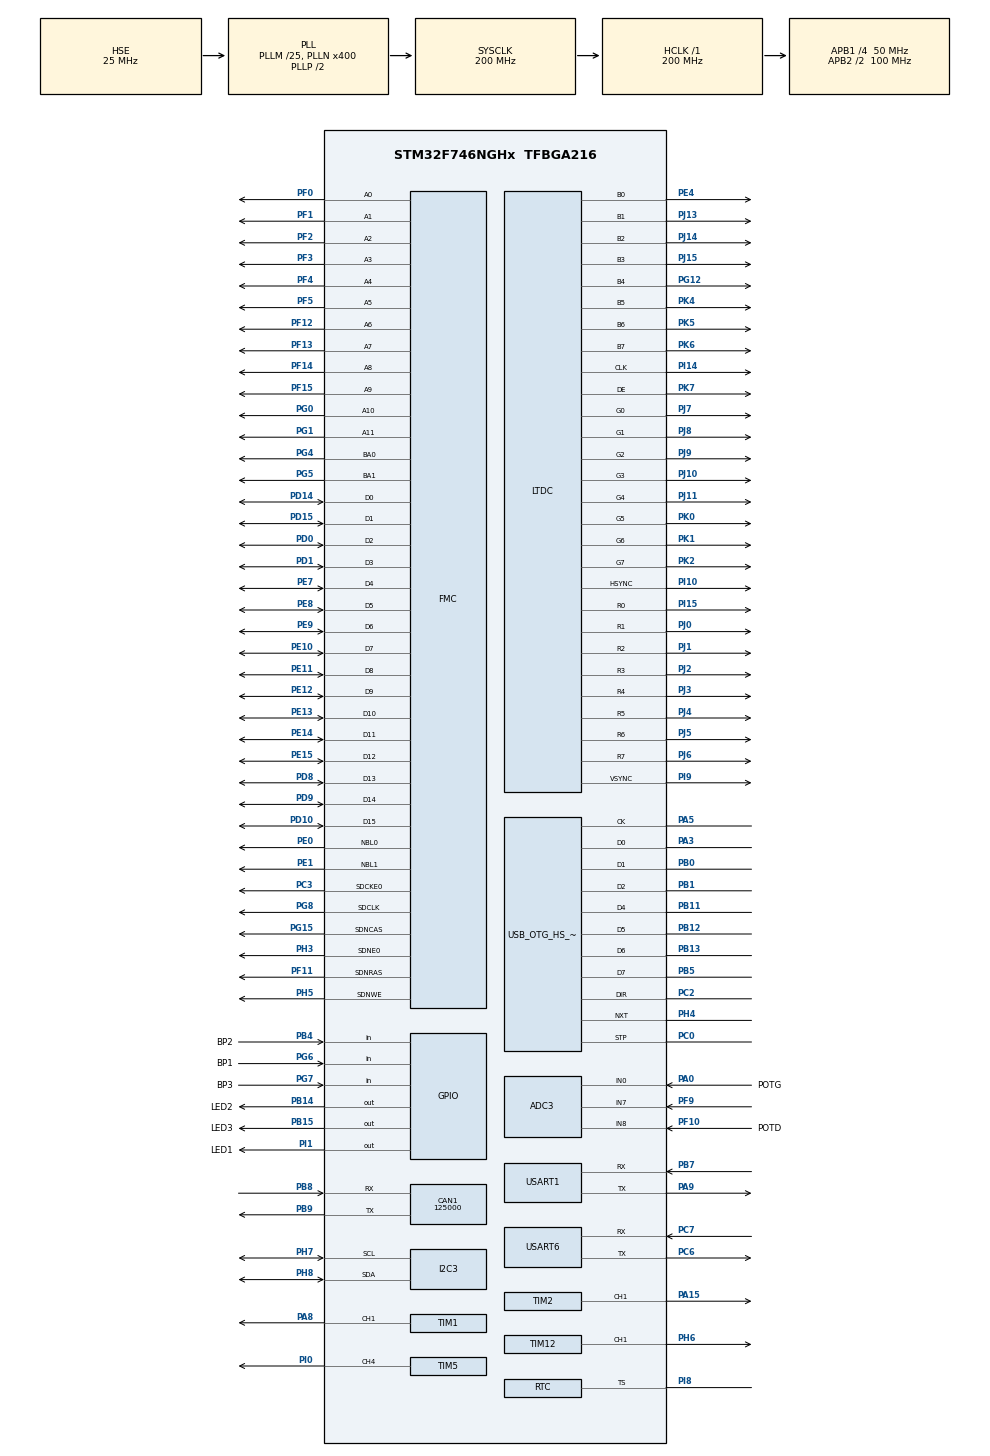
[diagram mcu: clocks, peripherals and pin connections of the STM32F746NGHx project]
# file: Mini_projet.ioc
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ADC1.Channel-0\#ChannelRegularConversion=ADC_CHANNEL_TEMPSENSOR
ADC1.NbrOfConversionFlag=1
ADC1.Rank-0\#ChannelRegularConversion=1
ADC1.SamplingTime-0\#ChannelRegularConversion=ADC_SAMPLETIME_3CYCLES
ADC1.master=1
ADC3.Channel-0\#ChannelRegularConversion=ADC_CHANNEL_0
ADC3.NbrOfConversionFlag=1
ADC3.Rank-0\#ChannelRegularConversion=1
ADC3.SamplingTime-0\#ChannelRegularConversion=ADC_SAMPLETIME_3CYCLES
CAN1.BS1=CAN_BS1_16TQ
CAN1.BS2=CAN_BS2_8TQ
CAN1.CalculateBaudRate=125000
CAN1.CalculateTimeBit=8000
CAN1.CalculateTimeQuantum=320.0
CAN1.SJW=CAN_SJW_2TQ
FMC.CASLatency1=FMC_SDRAM_CAS_LATENCY_3
FMC.ExitSelfRefreshDelay1=7
FMC.LoadToActiveDelay1=2
FMC.RCDDelay1=2
FMC.RPDelay1=2
FMC.RPDelay2=2
FMC.ReadBurst1=FMC_SDRAM_RBURST_ENABLE
FMC.ReadBurst2=FMC_SDRAM_RBURST_ENABLE
FMC.RowCycleDelay1=7
FMC.RowCycleDelay2=7
FMC.SDClockPeriod1=FMC_SDRAM_CLOCK_PERIOD_2
FMC.SDClockPeriod2=FMC_SDRAM_CLOCK_PERIOD_2
FMC.SelfRefreshTime1=4
FMC.WriteRecoveryTime1=3
FREERTOS.INCLUDE_vTaskDelayUntil=1
FREERTOS.Mutexes01=Mutex_layer,Dynamic,NULL
FREERTOS.Queues01=myQueue02,32,Message,0,Dynamic,NULL,NULL
FREERTOS.Tasks01=defaultTask,0,128,StartDefaultTask,Default,NULL,Dynamic,NULL,NULL;tache1,1,1024,affichage_1,Default,NULL,Dynamic,NULL,NULL;tache3,2,1024,update_state,Default,NULL,Dynamic,NULL,NULL;tache4,1,128,touch_confirm,Default,NULL,Dynamic,NULL,NULL
FREERTOS.configUSE_NEWLIB_REENTRANT=1
I2C3.Timing=0x00C0EAFF
LTDC.ActiveH=272
LTDC.ActiveW=480
LTDC.Alpha_L0=255
LTDC.BlendingFactor1_L0=LTDC_BLENDING_FACTOR1_PAxCA
LTDC.BlendingFactor2_L0=LTDC_BLENDING_FACTOR2_PAxCA
LTDC.FBStartAdress_L0=0xC0000000
LTDC.HBP=13
LTDC.HFP=32
LTDC.HSync=41
LTDC.ImageHeight_L0=272
LTDC.ImageWidth_L0=480
LTDC.Layers=0
LTDC.PixelFormat_L0=LTDC_PIXEL_FORMAT_RGB565
LTDC.VSync=10
LTDC.WindowX1_L0=480
LTDC.WindowY1_L0=272
Mcu.Family=STM32F7
Mcu.Name=STM32F746NGHx
Mcu.Package=TFBGA216
NVIC.CAN1_RX0_IRQn=true\:14\:0\:true\:false\:true\:true\:true\:true\:true
NVIC.DMA2D_IRQn=true\:5\:0\:false\:false\:true\:true\:true\:true\:true
NVIC.HASH_RNG_IRQn=true\:5\:0\:false\:false\:true\:true\:true\:true\:true
NVIC.LTDC_IRQn=true\:5\:0\:false\:false\:true\:true\:true\:true\:true
NVIC.PriorityGroup=NVIC_PRIORITYGROUP_4
NVIC.TIM6_DAC_IRQn=true\:15\:0\:false\:false\:true\:false\:false\:true\:true
NVIC.TimeBase=TIM6_DAC_IRQn
NVIC.TimeBaseIP=TIM6
PA0/WKUP.GPIO_Label=POTG
PA0/WKUP.Signal=ADCx_IN0
PA1.GPIO_Mode=GPIO_MODE_AF_PP
PA1.GPIO_PuPd=GPIO_NOPULL
PA1.GPIO_Speed=GPIO_SPEED_FREQ_VERY_HIGH
PA1.Signal=ETH_REF_CLK
PA10.GPIO_Mode=GPIO_MODE_AF_PP
PA10.GPIO_PuPd=GPIO_NOPULL
PA10.GPIO_Speed=GPIO_SPEED_FREQ_VERY_HIGH
PA10.Signal=USB_OTG_FS_ID
PA11.GPIO_Mode=GPIO_MODE_AF_PP
PA11.GPIO_PuPd=GPIO_NOPULL
PA11.GPIO_Speed=GPIO_SPEED_FREQ_VERY_HIGH
PA11.Signal=USB_OTG_FS_DM
PA12.GPIO_Mode=GPIO_MODE_AF_PP
PA12.GPIO_PuPd=GPIO_NOPULL
PA12.GPIO_Speed=GPIO_SPEED_FREQ_VERY_HIGH
PA12.Signal=USB_OTG_FS_DP
PA13.Signal=SYS_JTMS-SWDIO
PA14.Signal=SYS_JTCK-SWCLK
PA15.GPIO_ModeDefaultPP=GPIO_MODE_AF_PP
PA15.GPIO_PuPd=GPIO_NOPULL
PA15.GPIO_Speed=GPIO_SPEED_FREQ_LOW
PA15.Signal=S_TIM2_CH1_ETR
PA2.GPIO_Mode=GPIO_MODE_AF_PP
PA2.GPIO_PuPd=GPIO_NOPULL
PA2.GPIO_Speed=GPIO_SPEED_FREQ_VERY_HIGH
PA2.Signal=ETH_MDIO
PA3.GPIO_Mode=GPIO_MODE_AF_PP
PA3.GPIO_PuPd=GPIO_NOPULL
PA3.GPIO_Speed=GPIO_SPEED_FREQ_VERY_HIGH
PA3.Mode=Host_HS
PA3.Signal=USB_OTG_HS_ULPI_D0
PA4.GPIO_Mode=GPIO_MODE_AF_PP
PA4.GPIO_PuPd=GPIO_NOPULL
PA4.GPIO_Speed=GPIO_SPEED_FREQ_LOW
PA4.Signal=DCMI_HSYNC
PA5.GPIO_Mode=GPIO_MODE_AF_PP
PA5.GPIO_PuPd=GPIO_NOPULL
PA5.GPIO_Speed=GPIO_SPEED_FREQ_VERY_HIGH
PA5.Mode=Host_HS
PA5.Signal=USB_OTG_HS_ULPI_CK
PA6.Signal=DCMI_PIXCLK
PA7.GPIO_Mode=GPIO_MODE_AF_PP
PA7.GPIO_PuPd=GPIO_NOPULL
PA7.GPIO_Speed=GPIO_SPEED_FREQ_VERY_HIGH
PA7.Signal=ETH_CRS_DV
PA8.GPIO_ModeDefaultPP=GPIO_MODE_AF_PP
PA8.GPIO_PuPd=GPIO_NOPULL
PA8.GPIO_Speed=GPIO_SPEED_FREQ_LOW
PA8.Signal=S_TIM1_CH1
PA9.GPIO_Mode=GPIO_MODE_AF_PP
PA9.GPIO_ModeDefaultPP=GPIO_MODE_AF_PP
PA9.GPIO_PuPd=GPIO_NOPULL
PA9.GPIO_Speed=GPIO_SPEED_FREQ_VERY_HIGH
PA9.Mode=Asynchronous
PA9.Signal=USART1_TX
PB0.GPIO_Mode=GPIO_MODE_AF_PP
PB0.GPIO_PuPd=GPIO_NOPULL
PB0.GPIO_Speed=GPIO_SPEED_FREQ_VERY_HIGH
PB0.Mode=Host_HS
PB0.Signal=USB_OTG_HS_ULPI_D1
PB1.GPIO_Mode=GPIO_MODE_AF_PP
PB1.GPIO_PuPd=GPIO_NOPULL
PB1.GPIO_Speed=GPIO_SPEED_FREQ_VERY_HIGH
PB1.Mode=Host_HS
PB1.Signal=USB_OTG_HS_ULPI_D2
PB10.GPIO_Mode=GPIO_MODE_AF_PP
PB10.GPIO_PuPd=GPIO_NOPULL
PB10.GPIO_Speed=GPIO_SPEED_FREQ_VERY_HIGH
PB10.Signal=USB_OTG_HS_ULPI_D3
PB11.GPIO_Mode=GPIO_MODE_AF_PP
PB11.GPIO_PuPd=GPIO_NOPULL
PB11.GPIO_Speed=GPIO_SPEED_FREQ_VERY_HIGH
PB11.Mode=Host_HS
PB11.Signal=USB_OTG_HS_ULPI_D4
PB12.GPIO_Mode=GPIO_MODE_AF_PP
PB12.GPIO_PuPd=GPIO_NOPULL
PB12.GPIO_Speed=GPIO_SPEED_FREQ_VERY_HIGH
PB12.Mode=Host_HS
PB12.Signal=USB_OTG_HS_ULPI_D5
PB13.GPIO_Mode=GPIO_MODE_AF_PP
PB13.GPIO_PuPd=GPIO_NOPULL
PB13.GPIO_Speed=GPIO_SPEED_FREQ_VERY_HIGH
PB13.Mode=Host_HS
PB13.Signal=USB_OTG_HS_ULPI_D6
PB14.GPIO_Label=LED2
PB14.GPIO_ModeDefaultOutputPP=GPIO_MODE_OUTPUT_PP
PB14.GPIO_PuPd=GPIO_NOPULL
PB14.GPIO_Speed=GPIO_SPEED_FREQ_LOW
PB14.PinState=GPIO_PIN_RESET
PB14.Signal=GPIO_Output
PB15.GPIO_Label=LED3
PB15.GPIO_ModeDefaultOutputPP=GPIO_MODE_OUTPUT_PP
PB15.GPIO_PuPd=GPIO_NOPULL
PB15.GPIO_Speed=GPIO_SPEED_FREQ_LOW
PB15.PinState=GPIO_PIN_RESET
PB15.Signal=GPIO_Output
PB2.Signal=QUADSPI_CLK
PB3.Signal=SYS_JTDO-SWO
PB4.GPIO_Label=BP2
PB4.GPIO_Mode=GPIO_MODE_INPUT
PB4.GPIO_PuPd=GPIO_NOPULL
PB4.Signal=GPIO_Input
PB5.GPIO_Mode=GPIO_MODE_AF_PP
PB5.GPIO_PuPd=GPIO_NOPULL
PB5.GPIO_Speed=GPIO_SPEED_FREQ_VERY_HIGH
PB5.Mode=Host_HS
PB5.Signal=USB_OTG_HS_ULPI_D7
PB6.GPIO_Mode=GPIO_MODE_AF_PP
PB6.GPIO_PuPd=GPIO_NOPULL
PB6.GPIO_Speed=GPIO_SPEED_FREQ_VERY_HIGH
PB6.Signal=QUADSPI_BK1_NCS
PB7.GPIO_Mode=GPIO_MODE_AF_PP
PB7.GPIO_ModeDefaultPP=GPIO_MODE_AF_PP
PB7.GPIO_PuPd=GPIO_NOPULL
PB7.GPIO_Speed=GPIO_SPEED_FREQ_VERY_HIGH
PB7.Mode=Asynchronous
PB7.Signal=USART1_RX
PB8.Mode=CAN_Activate
PB8.Signal=CAN1_RX
PB9.Mode=CAN_Activate
PB9.Signal=CAN1_TX
PC0.GPIO_Mode=GPIO_MODE_AF_PP
PC0.GPIO_PuPd=GPIO_NOPULL
PC0.GPIO_Speed=GPIO_SPEED_FREQ_VERY_HIGH
PC0.Mode=Host_HS
PC0.Signal=USB_OTG_HS_ULPI_STP
PC1.GPIO_Mode=GPIO_MODE_AF_PP
PC1.GPIO_PuPd=GPIO_NOPULL
PC1.GPIO_Speed=GPIO_SPEED_FREQ_VERY_HIGH
PC1.Signal=ETH_MDC
PC10.GPIO_Mode=GPIO_MODE_AF_PP
PC10.GPIO_PuPd=GPIO_NOPULL
PC10.GPIO_Speed_High_Default=GPIO_SPEED_FREQ_VERY_HIGH
PC10.Signal=SDMMC1_D2
PC11.GPIO_Mode=GPIO_MODE_AF_PP
PC11.GPIO_PuPd=GPIO_NOPULL
PC11.GPIO_Speed_High_Default=GPIO_SPEED_FREQ_VERY_HIGH
PC11.Signal=SDMMC1_D3
PC12.GPIO_Mode=GPIO_MODE_AF_PP
PC12.GPIO_PuPd=GPIO_NOPULL
PC12.GPIO_Speed_High_Default=GPIO_SPEED_FREQ_VERY_HIGH
PC12.Signal=SDMMC1_CK
PC14/OSC32_IN.Mode=LSE-External-Oscillator
PC14/OSC32_IN.Signal=RCC_OSC32_IN
PC15/OSC32_OUT.Mode=LSE-External-Oscillator
PC15/OSC32_OUT.Signal=RCC_OSC32_OUT
PC2.GPIO_Mode=GPIO_MODE_AF_PP
PC2.GPIO_PuPd=GPIO_NOPULL
PC2.GPIO_Speed=GPIO_SPEED_FREQ_VERY_HIGH
PC2.Mode=Host_HS
PC2.Signal=USB_OTG_HS_ULPI_DIR
PC3.GPIO_Mode=GPIO_MODE_AF_PP
PC3.GPIO_PuPd=GPIO_NOPULL
PC3.GPIO_Speed_High_Default=GPIO_SPEED_FREQ_VERY_HIGH
PC3.Mode=SdramChipSelect1_1
PC3.Signal=FMC_SDCKE0
PC4.GPIO_Mode=GPIO_MODE_AF_PP
PC4.GPIO_PuPd=GPIO_NOPULL
PC4.GPIO_Speed=GPIO_SPEED_FREQ_VERY_HIGH
PC4.Signal=ETH_RXD0
PC5.GPIO_Mode=GPIO_MODE_AF_PP
PC5.GPIO_PuPd=GPIO_NOPULL
PC5.GPIO_Speed=GPIO_SPEED_FREQ_VERY_HIGH
PC5.Signal=ETH_RXD1
PC6.GPIO_ModeDefaultPP=GPIO_MODE_AF_PP
PC6.GPIO_PuPd=GPIO_NOPULL
PC6.GPIO_Speed=GPIO_SPEED_FREQ_VERY_HIGH
PC6.Mode=Asynchronous
PC6.Signal=USART6_TX
PC7.GPIO_ModeDefaultPP=GPIO_MODE_AF_PP
PC7.GPIO_PuPd=GPIO_NOPULL
PC7.GPIO_Speed=GPIO_SPEED_FREQ_VERY_HIGH
PC7.Mode=Asynchronous
PC7.Signal=USART6_RX
PC8.Signal=SDMMC1_D0
PC9.Signal=SDMMC1_D1
PD0.GPIO_Mode=GPIO_MODE_AF_PP
PD0.GPIO_PuPd=GPIO_NOPULL
PD0.GPIO_Speed_High_Default=GPIO_SPEED_FREQ_VERY_HIGH
PD0.Signal=FMC_D2_DA2
PD1.GPIO_Mode=GPIO_MODE_AF_PP
PD1.GPIO_PuPd=GPIO_NOPULL
PD1.GPIO_Speed_High_Default=GPIO_SPEED_FREQ_VERY_HIGH
PD1.Signal=FMC_D3_DA3
PD10.GPIO_Mode=GPIO_MODE_AF_PP
PD10.GPIO_PuPd=GPIO_NOPULL
PD10.GPIO_Speed_High_Default=GPIO_SPEED_FREQ_VERY_HIGH
PD10.Signal=FMC_D15_DA15
PD11.GPIO_Mode=GPIO_MODE_AF_PP
PD11.GPIO_PuPd=GPIO_NOPULL
PD11.GPIO_Speed=GPIO_SPEED_FREQ_VERY_HIGH
PD11.Signal=QUADSPI_BK1_IO0
PD12.GPIO_Mode=GPIO_MODE_AF_PP
PD12.GPIO_PuPd=GPIO_NOPULL
PD12.GPIO_Speed=GPIO_SPEED_FREQ_VERY_HIGH
PD12.Signal=QUADSPI_BK1_IO1
PD13.GPIO_Mode=GPIO_MODE_AF_PP
PD13.GPIO_PuPd=GPIO_NOPULL
PD13.GPIO_Speed=GPIO_SPEED_FREQ_VERY_HIGH
PD13.Signal=QUADSPI_BK1_IO3
PD14.GPIO_Mode=GPIO_MODE_AF_PP
PD14.GPIO_PuPd=GPIO_NOPULL
PD14.GPIO_Speed_High_Default=GPIO_SPEED_FREQ_VERY_HIGH
PD14.Signal=FMC_D0_DA0
PD15.GPIO_Mode=GPIO_MODE_AF_PP
PD15.GPIO_PuPd=GPIO_NOPULL
PD15.GPIO_Speed_High_Default=GPIO_SPEED_FREQ_VERY_HIGH
PD15.Signal=FMC_D1_DA1
PD2.GPIO_Mode=GPIO_MODE_AF_PP
PD2.GPIO_PuPd=GPIO_NOPULL
PD2.GPIO_Speed_High_Default=GPIO_SPEED_FREQ_VERY_HIGH
PD2.Signal=SDMMC1_CMD
PD3.GPIO_Mode=GPIO_MODE_AF_PP
PD3.GPIO_PuPd=GPIO_NOPULL
PD3.GPIO_Speed=GPIO_SPEED_FREQ_LOW
PD3.Signal=DCMI_D5
PD7.GPIO_Mode=GPIO_MODE_AF_PP
PD7.GPIO_PuPd=GPIO_NOPULL
PD7.GPIO_Speed=GPIO_SPEED_FREQ_LOW
PD7.Signal=SPDIFRX_IN0
PD8.GPIO_Mode=GPIO_MODE_AF_PP
PD8.GPIO_PuPd=GPIO_NOPULL
PD8.GPIO_Speed_High_Default=GPIO_SPEED_FREQ_VERY_HIGH
PD8.Signal=FMC_D13_DA13
PD9.GPIO_Mode=GPIO_MODE_AF_PP
PD9.GPIO_PuPd=GPIO_NOPULL
PD9.GPIO_Speed_High_Default=GPIO_SPEED_FREQ_VERY_HIGH
PD9.Signal=FMC_D14_DA14
PE0.GPIO_Mode=GPIO_MODE_AF_PP
PE0.GPIO_PuPd=GPIO_NOPULL
PE0.GPIO_Speed_High_Default=GPIO_SPEED_FREQ_VERY_HIGH
PE0.Signal=FMC_NBL0
PE1.GPIO_Mode=GPIO_MODE_AF_PP
PE1.GPIO_PuPd=GPIO_NOPULL
PE1.GPIO_Speed_High_Default=GPIO_SPEED_FREQ_VERY_HIGH
PE1.Signal=FMC_NBL1
PE10.GPIO_Mode=GPIO_MODE_AF_PP
PE10.GPIO_PuPd=GPIO_NOPULL
PE10.GPIO_Speed_High_Default=GPIO_SPEED_FREQ_VERY_HIGH
PE10.Signal=FMC_D7_DA7
PE11.GPIO_Mode=GPIO_MODE_AF_PP
PE11.GPIO_PuPd=GPIO_NOPULL
PE11.GPIO_Speed_High_Default=GPIO_SPEED_FREQ_VERY_HIGH
PE11.Signal=FMC_D8_DA8
PE12.GPIO_Mode=GPIO_MODE_AF_PP
PE12.GPIO_PuPd=GPIO_NOPULL
PE12.GPIO_Speed_High_Default=GPIO_SPEED_FREQ_VERY_HIGH
PE12.Signal=FMC_D9_DA9
PE13.GPIO_Mode=GPIO_MODE_AF_PP
PE13.GPIO_PuPd=GPIO_NOPULL
PE13.GPIO_Speed_High_Default=GPIO_SPEED_FREQ_VERY_HIGH
PE13.Signal=FMC_D10_DA10
PE14.GPIO_Mode=GPIO_MODE_AF_PP
PE14.GPIO_PuPd=GPIO_NOPULL
PE14.GPIO_Speed_High_Default=GPIO_SPEED_FREQ_VERY_HIGH
PE14.Signal=FMC_D11_DA11
PE15.GPIO_Mode=GPIO_MODE_AF_PP
PE15.GPIO_PuPd=GPIO_NOPULL
PE15.GPIO_Speed_High_Default=GPIO_SPEED_FREQ_VERY_HIGH
PE15.Signal=FMC_D12_DA12
PE2.GPIO_Mode=GPIO_MODE_AF_PP
PE2.GPIO_PuPd=GPIO_NOPULL
PE2.GPIO_Speed=GPIO_SPEED_FREQ_VERY_HIGH
PE2.Signal=QUADSPI_BK1_IO2
PE4.GPIO_Mode=GPIO_MODE_AF_PP
PE4.GPIO_PuPd=GPIO_NOPULL
PE4.GPIO_Speed=GPIO_SPEED_FREQ_LOW
PE4.Mode=RGB888
PE4.Signal=LTDC_B0
PE5.GPIO_Mode=GPIO_MODE_AF_PP
PE5.GPIO_PuPd=GPIO_NOPULL
PE5.GPIO_Speed=GPIO_SPEED_FREQ_LOW
PE5.Signal=DCMI_D6
PE6.GPIO_Mode=GPIO_MODE_AF_PP
PE6.GPIO_PuPd=GPIO_NOPULL
PE6.GPIO_Speed=GPIO_SPEED_FREQ_LOW
PE6.Signal=DCMI_D7
PE7.GPIO_Mode=GPIO_MODE_AF_PP
PE7.GPIO_PuPd=GPIO_NOPULL
PE7.GPIO_Speed_High_Default=GPIO_SPEED_FREQ_VERY_HIGH
PE7.Signal=FMC_D4_DA4
PE8.GPIO_Mode=GPIO_MODE_AF_PP
PE8.GPIO_PuPd=GPIO_NOPULL
PE8.GPIO_Speed_High_Default=GPIO_SPEED_FREQ_VERY_HIGH
PE8.Signal=FMC_D5_DA5
PE9.GPIO_Mode=GPIO_MODE_AF_PP
PE9.GPIO_PuPd=GPIO_NOPULL
PE9.GPIO_Speed_High_Default=GPIO_SPEED_FREQ_VERY_HIGH
PE9.Signal=FMC_D6_DA6
PF0.GPIO_Mode=GPIO_MODE_AF_PP
PF0.GPIO_PuPd=GPIO_NOPULL
PF0.GPIO_Speed_High_Default=GPIO_SPEED_FREQ_VERY_HIGH
PF0.Signal=FMC_A0
PF1.GPIO_Mode=GPIO_MODE_AF_PP
PF1.GPIO_PuPd=GPIO_NOPULL
PF1.GPIO_Speed_High_Default=GPIO_SPEED_FREQ_VERY_HIGH
PF1.Signal=FMC_A1
PF10.GPIO_Label=POTD
PF10.Mode=IN8
PF10.Signal=ADC3_IN8
PF11.GPIO_Mode=GPIO_MODE_AF_PP
PF11.GPIO_PuPd=GPIO_NOPULL
PF11.GPIO_Speed_High_Default=GPIO_SPEED_FREQ_VERY_HIGH
PF11.Signal=FMC_SDNRAS
PF12.GPIO_Mode=GPIO_MODE_AF_PP
PF12.GPIO_PuPd=GPIO_NOPULL
PF12.GPIO_Speed_High_Default=GPIO_SPEED_FREQ_VERY_HIGH
PF12.Signal=FMC_A6
PF13.GPIO_Mode=GPIO_MODE_AF_PP
PF13.GPIO_PuPd=GPIO_NOPULL
PF13.GPIO_Speed_High_Default=GPIO_SPEED_FREQ_VERY_HIGH
PF13.Signal=FMC_A7
PF14.GPIO_Mode=GPIO_MODE_AF_PP
PF14.GPIO_PuPd=GPIO_NOPULL
PF14.GPIO_Speed_High_Default=GPIO_SPEED_FREQ_VERY_HIGH
PF14.Signal=FMC_A8
PF15.GPIO_Mode=GPIO_MODE_AF_PP
PF15.GPIO_PuPd=GPIO_NOPULL
PF15.GPIO_Speed_High_Default=GPIO_SPEED_FREQ_VERY_HIGH
PF15.Signal=FMC_A9
PF2.GPIO_Mode=GPIO_MODE_AF_PP
PF2.GPIO_PuPd=GPIO_NOPULL
PF2.GPIO_Speed_High_Default=GPIO_SPEED_FREQ_VERY_HIGH
PF2.Signal=FMC_A2
PF3.GPIO_Mode=GPIO_MODE_AF_PP
PF3.GPIO_PuPd=GPIO_NOPULL
PF3.GPIO_Speed_High_Default=GPIO_SPEED_FREQ_VERY_HIGH
PF3.Signal=FMC_A3
PF4.GPIO_Mode=GPIO_MODE_AF_PP
PF4.GPIO_PuPd=GPIO_NOPULL
PF4.GPIO_Speed_High_Default=GPIO_SPEED_FREQ_VERY_HIGH
PF4.Signal=FMC_A4
PF5.GPIO_Mode=GPIO_MODE_AF_PP
PF5.GPIO_PuPd=GPIO_NOPULL
PF5.GPIO_Speed_High_Default=GPIO_SPEED_FREQ_VERY_HIGH
PF5.Signal=FMC_A5
PF6.GPIO_Mode=GPIO_MODE_ANALOG
PF6.GPIO_PuPd=GPIO_NOPULL
PF6.Signal=ADC3_IN4
PF7.GPIO_Mode=GPIO_MODE_ANALOG
PF7.GPIO_PuPd=GPIO_NOPULL
PF7.Signal=ADC3_IN5
PF8.GPIO_Mode=GPIO_MODE_ANALOG
PF8.GPIO_PuPd=GPIO_NOPULL
PF8.Signal=ADC3_IN6
PF9.GPIO_Mode=GPIO_MODE_ANALOG
PF9.GPIO_PuPd=GPIO_NOPULL
PF9.Mode=IN7
PF9.Signal=ADC3_IN7
PG0.GPIO_Mode=GPIO_MODE_AF_PP
PG0.GPIO_PuPd=GPIO_NOPULL
PG0.GPIO_Speed_High_Default=GPIO_SPEED_FREQ_VERY_HIGH
PG0.Signal=FMC_A10
PG1.GPIO_Mode=GPIO_MODE_AF_PP
PG1.GPIO_PuPd=GPIO_NOPULL
PG1.GPIO_Speed_High_Default=GPIO_SPEED_FREQ_VERY_HIGH
PG1.Signal=FMC_A11
PG10.GPIO_Mode=GPIO_MODE_AF_PP
PG10.GPIO_PuPd=GPIO_NOPULL
PG10.GPIO_Speed=GPIO_SPEED_FREQ_LOW
PG10.Signal=SAI2_SD_B
PG11.GPIO_Mode=GPIO_MODE_AF_PP
PG11.GPIO_PuPd=GPIO_NOPULL
PG11.GPIO_Speed=GPIO_SPEED_FREQ_VERY_HIGH
PG11.Signal=ETH_TX_EN
PG12.GPIO_Mode=GPIO_MODE_AF_PP
PG12.GPIO_PuPd=GPIO_NOPULL
PG12.GPIO_Speed=GPIO_SPEED_FREQ_LOW
PG12.Mode=RGB888
PG12.Signal=LTDC_B4
PG13.GPIO_Mode=GPIO_MODE_AF_PP
PG13.GPIO_PuPd=GPIO_NOPULL
PG13.GPIO_Speed=GPIO_SPEED_FREQ_VERY_HIGH
PG13.Signal=ETH_TXD0
PG14.GPIO_Mode=GPIO_MODE_AF_PP
PG14.GPIO_PuPd=GPIO_NOPULL
PG14.GPIO_Speed=GPIO_SPEED_FREQ_VERY_HIGH
PG14.Signal=ETH_TXD1
PG15.GPIO_Mode=GPIO_MODE_AF_PP
PG15.GPIO_PuPd=GPIO_NOPULL
PG15.GPIO_Speed_High_Default=GPIO_SPEED_FREQ_VERY_HIGH
PG15.Signal=FMC_SDNCAS
PG4.GPIO_Mode=GPIO_MODE_AF_PP
PG4.GPIO_PuPd=GPIO_NOPULL
PG4.GPIO_Speed_High_Default=GPIO_SPEED_FREQ_VERY_HIGH
PG4.Signal=FMC_A14_BA0
PG5.GPIO_Mode=GPIO_MODE_AF_PP
PG5.GPIO_PuPd=GPIO_NOPULL
PG5.GPIO_Speed_High_Default=GPIO_SPEED_FREQ_VERY_HIGH
PG5.Signal=FMC_A15_BA1
PG6.GPIO_Label=BP1
PG6.Signal=GPIO_Input
PG7.GPIO_Label=BP3
PG7.GPIO_Mode=GPIO_MODE_INPUT
PG7.GPIO_PuPd=GPIO_NOPULL
PG7.Signal=GPIO_Input
PG8.GPIO_Mode=GPIO_MODE_AF_PP
PG8.GPIO_PuPd=GPIO_NOPULL
PG8.GPIO_Speed_High_Default=GPIO_SPEED_FREQ_VERY_HIGH
PG8.Signal=FMC_SDCLK
PG9.GPIO_Mode=GPIO_MODE_AF_PP
PG9.GPIO_PuPd=GPIO_NOPULL
PG9.GPIO_Speed=GPIO_SPEED_FREQ_LOW
PG9.Signal=DCMI_VSYNC
PH0/OSC_IN.Mode=HSE-External-Oscillator
PH0/OSC_IN.Signal=RCC_OSC_IN
PH1/OSC_OUT.Mode=HSE-External-Oscillator
PH1/OSC_OUT.Signal=RCC_OSC_OUT
PH10.GPIO_Mode=GPIO_MODE_AF_PP
PH10.GPIO_PuPd=GPIO_NOPULL
PH10.GPIO_Speed=GPIO_SPEED_FREQ_LOW
PH10.Signal=DCMI_D1
PH11.GPIO_Mode=GPIO_MODE_AF_PP
PH11.GPIO_PuPd=GPIO_NOPULL
PH11.GPIO_Speed=GPIO_SPEED_FREQ_LOW
PH11.Signal=DCMI_D2
PH12.GPIO_Mode=GPIO_MODE_AF_PP
PH12.GPIO_PuPd=GPIO_NOPULL
PH12.GPIO_Speed=GPIO_SPEED_FREQ_LOW
PH12.Signal=DCMI_D3
PH14.GPIO_Mode=GPIO_MODE_AF_PP
PH14.GPIO_PuPd=GPIO_NOPULL
PH14.GPIO_Speed=GPIO_SPEED_FREQ_LOW
PH14.Signal=DCMI_D4
PH3.GPIO_Mode=GPIO_MODE_AF_PP
PH3.GPIO_PuPd=GPIO_NOPULL
PH3.GPIO_Speed_High_Default=GPIO_SPEED_FREQ_VERY_HIGH
PH3.Mode=SdramChipSelect1_1
PH3.Signal=FMC_SDNE0
PH4.GPIO_Mode=GPIO_MODE_AF_PP
PH4.GPIO_PuPd=GPIO_NOPULL
PH4.GPIO_Speed=GPIO_SPEED_FREQ_VERY_HIGH
PH4.Mode=Host_HS
PH4.Signal=USB_OTG_HS_ULPI_NXT
PH5.GPIO_Mode=GPIO_MODE_AF_PP
PH5.GPIO_PuPd=GPIO_NOPULL
PH5.GPIO_Speed_High_Default=GPIO_SPEED_FREQ_VERY_HIGH
PH5.Signal=FMC_SDNWE
PH6.GPIO_ModeDefaultPP=GPIO_MODE_AF_PP
PH6.GPIO_PuPd=GPIO_NOPULL
PH6.GPIO_Speed=GPIO_SPEED_FREQ_LOW
PH6.Signal=S_TIM12_CH1
PH7.GPIO_Mode=GPIO_MODE_AF_OD
PH7.GPIO_Pu=GPIO_PULLUP
PH7.GPIO_Speed=GPIO_SPEED_FREQ_VERY_HIGH
PH7.Mode=I2C
PH7.Signal=I2C3_SCL
PH8.GPIO_Mode=GPIO_MODE_AF_OD
PH8.GPIO_Pu=GPIO_PULLUP
PH8.GPIO_Speed=GPIO_SPEED_FREQ_VERY_HIGH
PH8.Mode=I2C
PH8.Signal=I2C3_SDA
PH9.GPIO_Mode=GPIO_MODE_AF_PP
PH9.GPIO_PuPd=GPIO_NOPULL
PH9.GPIO_Speed=GPIO_SPEED_FREQ_LOW
PH9.Signal=DCMI_D0
PI0.GPIO_ModeDefaultPP=GPIO_MODE_AF_PP
PI0.GPIO_PuPd=GPIO_NOPULL
PI0.GPIO_Speed=GPIO_SPEED_FREQ_LOW
PI0.Signal=S_TIM5_CH4
PI1.GPIO_Label=LED1
PI1.GPIO_ModeDefaultOutputPP=GPIO_MODE_OUTPUT_PP
PI1.GPIO_PuPd=GPIO_NOPULL
PI1.GPIO_Speed=GPIO_SPEED_FREQ_LOW
PI1.PinState=GPIO_PIN_RESET
PI1.Signal=GPIO_Output
PI10.GPIO_Mode=GPIO_MODE_AF_PP
PI10.GPIO_PuPd=GPIO_NOPULL
PI10.GPIO_Speed=GPIO_SPEED_FREQ_LOW
PI10.Mode=RGB888
PI10.Signal=LTDC_HSYNC
PI14.GPIO_Mode=GPIO_MODE_AF_PP
PI14.GPIO_PuPd=GPIO_NOPULL
PI14.GPIO_Speed=GPIO_SPEED_FREQ_LOW
PI14.Mode=RGB888
PI14.Signal=LTDC_CLK
PI15.GPIO_Mode=GPIO_MODE_AF_PP
PI15.GPIO_PuPd=GPIO_NOPULL
PI15.GPIO_Speed=GPIO_SPEED_FREQ_LOW
PI15.Mode=RGB888
PI15.Signal=LTDC_R0
PI4.GPIO_Mode=GPIO_MODE_AF_PP
PI4.GPIO_PuPd=GPIO_NOPULL
PI4.GPIO_Speed=GPIO_SPEED_FREQ_LOW
PI4.Signal=SAI2_MCLK_A
PI5.GPIO_Mode=GPIO_MODE_AF_PP
PI5.GPIO_PuPd=GPIO_NOPULL
PI5.GPIO_Speed=GPIO_SPEED_FREQ_LOW
PI5.Signal=SAI2_SCK_A
PI6.GPIO_Mode=GPIO_MODE_AF_PP
PI6.GPIO_PuPd=GPIO_NOPULL
PI6.GPIO_Speed=GPIO_SPEED_FREQ_LOW
PI6.Signal=SAI2_SD_A
PI7.GPIO_Mode=GPIO_MODE_AF_PP
PI7.GPIO_PuPd=GPIO_NOPULL
PI7.GPIO_Speed=GPIO_SPEED_FREQ_LOW
PI7.Signal=SAI2_FS_A
PI8.Mode=Timestamp enabled - Input Enabled to TS
PI8.Signal=RTC_TS
PI9.GPIO_Mode=GPIO_MODE_AF_PP
PI9.GPIO_PuPd=GPIO_NOPULL
PI9.GPIO_Speed=GPIO_SPEED_FREQ_LOW
PI9.Mode=RGB888
PI9.Signal=LTDC_VSYNC
PJ0.GPIO_Mode=GPIO_MODE_AF_PP
PJ0.GPIO_PuPd=GPIO_NOPULL
PJ0.GPIO_Speed=GPIO_SPEED_FREQ_LOW
PJ0.Mode=RGB888
PJ0.Signal=LTDC_R1
PJ1.GPIO_Mode=GPIO_MODE_AF_PP
PJ1.GPIO_PuPd=GPIO_NOPULL
PJ1.GPIO_Speed=GPIO_SPEED_FREQ_LOW
PJ1.Mode=RGB888
PJ1.Signal=LTDC_R2
PJ10.GPIO_Mode=GPIO_MODE_AF_PP
PJ10.GPIO_PuPd=GPIO_NOPULL
PJ10.GPIO_Speed=GPIO_SPEED_FREQ_LOW
PJ10.Mode=RGB888
PJ10.Signal=LTDC_G3
PJ11.GPIO_Mode=GPIO_MODE_AF_PP
PJ11.GPIO_PuPd=GPIO_NOPULL
PJ11.GPIO_Speed=GPIO_SPEED_FREQ_LOW
PJ11.Mode=RGB888
PJ11.Signal=LTDC_G4
PJ13.GPIO_Mode=GPIO_MODE_AF_PP
PJ13.GPIO_PuPd=GPIO_NOPULL
PJ13.GPIO_Speed=GPIO_SPEED_FREQ_LOW
PJ13.Mode=RGB888
PJ13.Signal=LTDC_B1
PJ14.GPIO_Mode=GPIO_MODE_AF_PP
PJ14.GPIO_PuPd=GPIO_NOPULL
PJ14.GPIO_Speed=GPIO_SPEED_FREQ_LOW
PJ14.Mode=RGB888
PJ14.Signal=LTDC_B2
PJ15.GPIO_Mode=GPIO_MODE_AF_PP
PJ15.GPIO_PuPd=GPIO_NOPULL
PJ15.GPIO_Speed=GPIO_SPEED_FREQ_LOW
PJ15.Mode=RGB888
PJ15.Signal=LTDC_B3
PJ2.GPIO_Mode=GPIO_MODE_AF_PP
PJ2.GPIO_PuPd=GPIO_NOPULL
PJ2.GPIO_Speed=GPIO_SPEED_FREQ_LOW
PJ2.Mode=RGB888
PJ2.Signal=LTDC_R3
PJ3.GPIO_Mode=GPIO_MODE_AF_PP
PJ3.GPIO_PuPd=GPIO_NOPULL
PJ3.GPIO_Speed=GPIO_SPEED_FREQ_LOW
PJ3.Mode=RGB888
PJ3.Signal=LTDC_R4
PJ4.GPIO_Mode=GPIO_MODE_AF_PP
PJ4.GPIO_PuPd=GPIO_NOPULL
PJ4.GPIO_Speed=GPIO_SPEED_FREQ_LOW
PJ4.Mode=RGB888
PJ4.Signal=LTDC_R5
PJ5.GPIO_Mode=GPIO_MODE_AF_PP
PJ5.GPIO_PuPd=GPIO_NOPULL
PJ5.GPIO_Speed=GPIO_SPEED_FREQ_LOW
PJ5.Mode=RGB888
PJ5.Signal=LTDC_R6
PJ6.GPIO_Mode=GPIO_MODE_AF_PP
PJ6.GPIO_PuPd=GPIO_NOPULL
PJ6.GPIO_Speed=GPIO_SPEED_FREQ_LOW
PJ6.Mode=RGB888
PJ6.Signal=LTDC_R7
PJ7.GPIO_Mode=GPIO_MODE_AF_PP
PJ7.GPIO_PuPd=GPIO_NOPULL
PJ7.GPIO_Speed=GPIO_SPEED_FREQ_LOW
PJ7.Mode=RGB888
PJ7.Signal=LTDC_G0
PJ8.GPIO_Mode=GPIO_MODE_AF_PP
PJ8.GPIO_PuPd=GPIO_NOPULL
PJ8.GPIO_Speed=GPIO_SPEED_FREQ_LOW
PJ8.Mode=RGB888
PJ8.Signal=LTDC_G1
PJ9.GPIO_Mode=GPIO_MODE_AF_PP
PJ9.GPIO_PuPd=GPIO_NOPULL
PJ9.GPIO_Speed=GPIO_SPEED_FREQ_LOW
PJ9.Mode=RGB888
PJ9.Signal=LTDC_G2
PK0.GPIO_Mode=GPIO_MODE_AF_PP
PK0.GPIO_PuPd=GPIO_NOPULL
PK0.GPIO_Speed=GPIO_SPEED_FREQ_LOW
PK0.Mode=RGB888
PK0.Signal=LTDC_G5
PK1.GPIO_Mode=GPIO_MODE_AF_PP
PK1.GPIO_PuPd=GPIO_NOPULL
PK1.GPIO_Speed=GPIO_SPEED_FREQ_LOW
PK1.Mode=RGB888
PK1.Signal=LTDC_G6
PK2.GPIO_Mode=GPIO_MODE_AF_PP
PK2.GPIO_PuPd=GPIO_NOPULL
PK2.GPIO_Speed=GPIO_SPEED_FREQ_LOW
PK2.Mode=RGB888
PK2.Signal=LTDC_G7
PK4.GPIO_Mode=GPIO_MODE_AF_PP
PK4.GPIO_PuPd=GPIO_NOPULL
PK4.GPIO_Speed=GPIO_SPEED_FREQ_LOW
PK4.Mode=RGB888
PK4.Signal=LTDC_B5
PK5.GPIO_Mode=GPIO_MODE_AF_PP
PK5.GPIO_PuPd=GPIO_NOPULL
PK5.GPIO_Speed=GPIO_SPEED_FREQ_LOW
PK5.Mode=RGB888
PK5.Signal=LTDC_B6
PK6.GPIO_Mode=GPIO_MODE_AF_PP
PK6.GPIO_PuPd=GPIO_NOPULL
PK6.GPIO_Speed=GPIO_SPEED_FREQ_LOW
PK6.Mode=RGB888
PK6.Signal=LTDC_B7
PK7.GPIO_Mode=GPIO_MODE_AF_PP
PK7.GPIO_PuPd=GPIO_NOPULL
PK7.GPIO_Speed=GPIO_SPEED_FREQ_LOW
PK7.Mode=RGB888
PK7.Signal=LTDC_DE
ProjectManager.HeapSize=0x200
ProjectManager.StackSize=0x400
ProjectManager.TargetToolchain=STM32CubeIDE
RCC.AHBFreq_Value=200000000
RCC.APB1CLKDivider=RCC_HCLK_DIV4
RCC.APB1Freq_Value=50000000
RCC.APB1TimFreq_Value=100000000
RCC.APB2CLKDivider=RCC_HCLK_DIV2
RCC.APB2Freq_Value=100000000
RCC.APB2TimFreq_Value=200000000
RCC.CortexFreq_Value=200000000
RCC.HCLKFreq_Value=200000000
RCC.HSE_VALUE=25000000
RCC.HSI_VALUE=16000000
RCC.PLL48CLockSelection=RCC_CLK48SOURCE_PLLSAIP
RCC.PLLI2SN=100
RCC.PLLM=25
RCC.PLLN=400
RCC.PLLQ=9
RCC.PLLSAIN=384
RCC.PLLSAIP=RCC_PLLSAIP_DIV8
RCC.PLLSAIR=5
RCC.PLLSAIRDiv=RCC_PLLSAIDIVR_8
RCC.PLLSourceVirtual=RCC_PLLSOURCE_HSE
RCC.SDMMCClockSelection=RCC_SDMMC1CLKSOURCE_CLK48
RCC.SYSCLKFreq_VALUE=200000000
RCC.SYSCLKSource=RCC_SYSCLKSOURCE_PLLCLK
RCC.USBFreq_Value=48000000
RCC.VCOOutputFreq_Value=400000000
RTC.Alarm-Alarm\ A=RTC_ALARM_A
RTC.Alarm_B-Alarm\ B=RTC_ALARM_B
SH.ADCx_IN0.0=ADC3_IN0,IN0
SH.FMC_A0.0=FMC_A0,12b-sda1
SH.FMC_A1.0=FMC_A1,12b-sda1
SH.FMC_A10.0=FMC_A10,12b-sda1
SH.FMC_A11.0=FMC_A11,12b-sda1
SH.FMC_A14_BA0.0=FMC_BA0,FourSdramBanks1
SH.FMC_A15_BA1.0=FMC_BA1,FourSdramBanks1
SH.FMC_A2.0=FMC_A2,12b-sda1
SH.FMC_A3.0=FMC_A3,12b-sda1
SH.FMC_A4.0=FMC_A4,12b-sda1
SH.FMC_A5.0=FMC_A5,12b-sda1
SH.FMC_A6.0=FMC_A6,12b-sda1
SH.FMC_A7.0=FMC_A7,12b-sda1
SH.FMC_A8.0=FMC_A8,12b-sda1
SH.FMC_A9.0=FMC_A9,12b-sda1
SH.FMC_D0_DA0.0=FMC_D0,sd-16b-d1
SH.FMC_D10_DA10.0=FMC_D10,sd-16b-d1
SH.FMC_D11_DA11.0=FMC_D11,sd-16b-d1
SH.FMC_D12_DA12.0=FMC_D12,sd-16b-d1
SH.FMC_D13_DA13.0=FMC_D13,sd-16b-d1
SH.FMC_D14_DA14.0=FMC_D14,sd-16b-d1
SH.FMC_D15_DA15.0=FMC_D15,sd-16b-d1
SH.FMC_D1_DA1.0=FMC_D1,sd-16b-d1
SH.FMC_D2_DA2.0=FMC_D2,sd-16b-d1
SH.FMC_D3_DA3.0=FMC_D3,sd-16b-d1
SH.FMC_D4_DA4.0=FMC_D4,sd-16b-d1
SH.FMC_D5_DA5.0=FMC_D5,sd-16b-d1
SH.FMC_D6_DA6.0=FMC_D6,sd-16b-d1
SH.FMC_D7_DA7.0=FMC_D7,sd-16b-d1
SH.FMC_D8_DA8.0=FMC_D8,sd-16b-d1
SH.FMC_D9_DA9.0=FMC_D9,sd-16b-d1
SH.FMC_NBL0.0=FMC_NBL0,Sd2ByteEnable1
SH.FMC_NBL1.0=FMC_NBL1,Sd2ByteEnable1
SH.FMC_SDCLK.0=FMC_SDCLK,12b-sda1
SH.FMC_SDNCAS.0=FMC_SDNCAS,12b-sda1
SH.FMC_SDNRAS.0=FMC_SDNRAS,12b-sda1
SH.FMC_SDNWE.0=FMC_SDNWE,12b-sda1
SH.S_TIM12_CH1.0=TIM12_CH1,PWM Generation1 CH1
SH.S_TIM1_CH1.0=TIM1_CH1,PWM Generation1 CH1
SH.S_TIM2_CH1_ETR.0=TIM2_CH1,PWM Generation1 CH1
SH.S_TIM5_CH4.0=TIM5_CH4,PWM Generation4 CH4
TIM1.Channel-PWM\ Generation1\ CH1=TIM_CHANNEL_1
TIM12.Channel-PWM\ Generation1\ CH1=TIM_CHANNEL_1
TIM2.Channel-PWM\ Generation1\ CH1=TIM_CHANNEL_1
TIM5.Channel-PWM\ Generation4\ CH4=TIM_CHANNEL_4
USART1.DMADisableonRxErrorParam=ADVFEATURE_DMA_DISABLEONRXERROR
USART1.OverrunDisableParam=ADVFEATURE_OVERRUN_DISABLE
USART1.VirtualMode-Asynchronous=VM_ASYNC
USART6.DMADisableonRxErrorParam=ADVFEATURE_DMA_DISABLEONRXERROR
USART6.OverrunDisableParam=ADVFEATURE_OVERRUN_ENABLE
USART6.VirtualMode-Asynchronous=VM_ASYNC
VP_ADC1_TempSens_Input.Mode=IN-TempSens
VP_DMA2D_VS_DMA2D.Mode=DMA2D_Activate
VP_FREERTOS_VS_CMSIS_V1.Mode=CMSIS_V1
VP_RNG_VS_RNG.Mode=RNG_Activate
VP_RTC_VS_RTC_Activate.Mode=RTC_Enabled
VP_RTC_VS_RTC_Alarm_A_Intern.Mode=Alarm A
VP_RTC_VS_RTC_Alarm_B_Intern.Mode=Alarm B
VP_RTC_VS_RTC_Calendar.Mode=RTC_Calendar
VP_SYS_VS_tim6.Mode=TIM6
VP_TIM1_VS_ClockSourceINT.Mode=Internal
VP_TIM2_VS_ClockSourceINT.Mode=Internal
VP_TIM3_VS_ClockSourceINT.Mode=Internal
VP_TIM5_VS_ClockSourceINT.Mode=Internal
VP_TIM8_VS_ClockSourceINT.Mode=Internal
board=STM32F746G-DISCO

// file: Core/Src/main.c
/* USER CODE BEGIN Header */
/**
 ******************************************************************************
 * @file           : main.c
 * @brief          : Main program body
 ******************************************************************************
 * @attention
 *
 * Copyright (c) 2022 STMicroelectronics.
 * All rights reserved.
 *
 * This software is licensed under terms that can be found in the LICENSE file
 * in the root directory of this software component.
 * If no LICENSE file comes with this software, it is provided AS-IS.
 *
 ******************************************************************************
 */
/* USER CODE END Header */
#include "main.h"
#include "cmsis_os.h"
#include "adc.h"
#include "can.h"
#include "dma2d.h"
#include "i2c.h"
#include "ltdc.h"
#include "rng.h"
#include "rtc.h"
#include "tim.h"
#include "usart.h"
#include "gpio.h"
#include "fmc.h"

/* USER CODE BEGIN Includes */
#include "stm32746g_discovery_lcd.h"
#include "stm32746g_discovery_ts.h"
#include "stdio.h"
#include "table.h"
/* USER CODE END Includes */

/* USER CODE BEGIN PV */
uint8_t caractere_recu;
CAN_HandleTypeDef CanHandle;
CAN_TxHeaderTypeDef TxHeader1;
CAN_TxHeaderTypeDef TxHeader2;
CAN_RxHeaderTypeDef RxHeader;
uint8_t TxData1[4];
uint8_t TxData2[8];
uint8_t RxData[4];
uint32_t TxMailbox;

extern int ID;
//int ID=1; // est la MEME valeur que celui dans freertos.c

// à modifier l'ID
/* USER CODE END PV */

void SystemClock_Config(void);
void PeriphCommonClock_Config(void);
void MX_FREERTOS_Init(void);

int main(void)
{
  /* USER CODE BEGIN 1 */
	char text[50]={};
	char text2[50]={};
	static TS_StateTypeDef  TS_State;
	uint32_t potl,potr,joystick_h, joystick_v;
	ADC_ChannelConfTypeDef sConfig = {0};
	sConfig.Rank = ADC_REGULAR_RANK_1;
	sConfig.SamplingTime = ADC_SAMPLETIME_3CYCLES;

	//bus CAN
	uint32_t truc_can;
	CAN_FilterTypeDef sFilterConfig;

//	/*CODE TP1*/
//	char msg[50]={};
//	char recep[50] ;
//	char retour[50]={};
//
//	uint8_t time[3]={};
//	uint8_t date[3]={};
//
//	uint16_t pos_v=130;
//	uint16_t pos_h=240;
//
//	int16_t vit_v=0;
//	int16_t vit_h=0;
//
//
//	//        TP2 variables
//	RTC_TimeTypeDef time1, time2;
//	RTC_DateTypeDef date1, date2;
	uint32_t i,millisecond1,millisecond2,value;

  /* USER CODE END 1 */

  /* MCU Configuration--------------------------------------------------------*/

  /* Reset of all peripherals, Initializes the Flash interface and the Systick. */
  HAL_Init();

  /* Configure the system clock */
  SystemClock_Config();

/* Configure the peripherals common clocks */
  PeriphCommonClock_Config();

  /* Initialize all configured peripherals */
  MX_GPIO_Init();
  MX_ADC3_Init();
  MX_DMA2D_Init();
  MX_FMC_Init();
  MX_I2C3_Init();
  MX_LTDC_Init();
  MX_RTC_Init();
  MX_TIM1_Init();
  MX_TIM2_Init();
  MX_TIM3_Init();
  MX_TIM5_Init();
  MX_TIM8_Init();
  MX_TIM12_Init();
  MX_USART1_UART_Init();
  MX_USART6_UART_Init();
  MX_CAN1_Init();
  MX_ADC1_Init();
  MX_RNG_Init();
  /* USER CODE BEGIN 2 */
	BSP_LCD_Init();
	BSP_LCD_LayerDefaultInit(0, LCD_FB_START_ADDRESS);
	BSP_LCD_LayerDefaultInit(1, LCD_FB_START_ADDRESS+ BSP_LCD_GetXSize()*BSP_LCD_GetYSize()*4);
	BSP_LCD_DisplayOn();

	//layer 0 : table background,UNO,pioche,cartes adversaires
	BSP_LCD_SelectLayer(0);
	BSP_LCD_Clear(LCD_COLOR_RED);
	BSP_LCD_DrawBitmap(0,0,(uint8_t*)_actable);

	//layer 1 : carte dessous,playing flag,UNO blink
	BSP_LCD_SelectLayer(1);
	BSP_LCD_Clear(00);
	BSP_LCD_SetFont(&Font12);
	BSP_LCD_SetTextColor(LCD_COLOR_BLUE);
	BSP_LCD_SetBackColor(00);

	//IL NY A QUE 2 COUCHES / ON DOIT JUSTE
	//pour carte dessus/dessous, afficher l'une puis l'autre sur une meme tache

	//layer 2 : carte dessus,nb joueurs, nb cartes,WIN/LOSE/BEGIN/CHARGEMENT/CONNEXION

	//begin touchscreen
	BSP_TS_Init(BSP_LCD_GetXSize(), BSP_LCD_GetYSize());

	//pour le TP3 la liaision UART interruptions

	//HAL_UART_Receive_IT(&huart1,&caractere_recu,1);

	/* Commencer le bus CAN
	 *
	 *
	 */
	/*##-2- Configure the CAN Filter ###########################################*/
	sFilterConfig.FilterBank = 0;
	sFilterConfig.FilterMode = CAN_FILTERMODE_IDMASK;
	sFilterConfig.FilterScale = CAN_FILTERSCALE_32BIT;
	sFilterConfig.FilterIdHigh = 0x000; //ON ECOUTE TOUT
	sFilterConfig.FilterIdLow = 0x000;
	sFilterConfig.FilterMaskIdHigh = 0x0000;
	sFilterConfig.FilterMaskIdLow = 0x0000;
	sFilterConfig.FilterFIFOAssignment = CAN_RX_FIFO0;
	sFilterConfig.FilterActivation = ENABLE;
	sFilterConfig.SlaveStartFilterBank = 14;

	if (HAL_CAN_ConfigFilter(&hcan1, &sFilterConfig) != HAL_OK) {
		/* Filter configuration Error */
		Error_Handler();
	}

	//IL FAUT QUAND MEME ACTIVER LA RECEPTION
    HAL_CAN_ActivateNotification(&hcan1, CAN_IT_RX_FIFO0_MSG_PENDING);

	/*##-3- Start the CAN peripheral ###########################################*/
	if (HAL_CAN_Start(&hcan1) != HAL_OK) {
		/* Start Error */
		Error_Handler();
	}
	TxHeader1.StdId = 0x410;//importance du MESSAGE
	TxHeader1.ExtId = 0x01; //peu importe, on est en ID 11 bits (CAN_ID_STD)
	TxHeader1.RTR = CAN_RTR_DATA;
	TxHeader1.IDE = CAN_ID_STD;
	TxHeader1.DLC = 4;//data length
	TxHeader1.TransmitGlobalTime = DISABLE;

	//on a pas beson d'envoyer 2 choses à la fois pas de Tx2Header

  /* USER CODE END 2 */

  /* Call init function for freertos objects (in freertos.c) */
  MX_FREERTOS_Init();

  /* Start scheduler */
  osKernelStart();

  /* We should never get here as control is now taken by the scheduler */
  /* Infinite loop */
  /* USER CODE BEGIN WHILE */

	while (1)
	{
		//   RECEVOIR
		if (HAL_CAN_GetRxMessage(&hcan1, CAN_RX_FIFO0, &RxHeader, RxData)
				== HAL_OK) {
			//HAL_GPIO_TogglePin(LED3_GPIO_Port, LED3_Pin);

			sprintf(text, "ID %3X data ", (unsigned int)RxHeader.StdId);

			for (i = 0; i < RxHeader.DLC; i++) {
				sprintf(text2, "%2X ", RxData[i]);
				strcat(text, text2);
			}

			BSP_LCD_DisplayStringAt(10, 255, (uint8_t*) text, LEFT_MODE);
		}

		//     ENVOYER
		TxData1[0] = (2000) >> 8; //valeur de 0 à 3000 en 0.1 km/h (avec offset de -2000)
		TxData1[1] = (2000) & 0xFF; //valeur de 0 à 3000 en 0.1 km/h (avec offset de -2000)
		TxData1[2] = (20000) >> 8; // valeur de -12000 à 12000 en tour/min (avec offset de -20000)
		TxData1[3] = (20000) ;
		HAL_CAN_AddTxMessage(&hcan1, &TxHeader1, TxData1, &truc_can);

		TxData2[0] = 2500; //valeur de 0 à 3000 en 0.1 km/h (avec offset de -2000)
		HAL_CAN_AddTxMessage(&hcan1, &TxHeader2, TxData2, &truc_can);

    /* USER CODE END WHILE */

	}
}

void SystemClock_Config(void)
{
  RCC_OscInitTypeDef RCC_OscInitStruct = {0};
  RCC_ClkInitTypeDef RCC_ClkInitStruct = {0};

  /** Configure LSE Drive Capability
  */
  HAL_PWR_EnableBkUpAccess();

  /** Configure the main internal regulator output voltage
  */
  __HAL_RCC_PWR_CLK_ENABLE();
  __HAL_PWR_VOLTAGESCALING_CONFIG(PWR_REGULATOR_VOLTAGE_SCALE1);

  /** Initializes the RCC Oscillators according to the specified parameters
  * in the RCC_OscInitTypeDef structure.
  */
  RCC_OscInitStruct.OscillatorType = RCC_OSCILLATORTYPE_LSI|RCC_OSCILLATORTYPE_HSE;
  RCC_OscInitStruct.HSEState = RCC_HSE_ON;
  RCC_OscInitStruct.LSIState = RCC_LSI_ON;
  RCC_OscInitStruct.PLL.PLLState = RCC_PLL_ON;
  RCC_OscInitStruct.PLL.PLLSource = RCC_PLLSOURCE_HSE;
  RCC_OscInitStruct.PLL.PLLM = 25;
  RCC_OscInitStruct.PLL.PLLN = 400;
  RCC_OscInitStruct.PLL.PLLP = RCC_PLLP_DIV2;
  RCC_OscInitStruct.PLL.PLLQ = 9;
  if (HAL_RCC_OscConfig(&RCC_OscInitStruct) != HAL_OK)
  {
    Error_Handler();
  }

  /** Activate the Over-Drive mode
  */
  if (HAL_PWREx_EnableOverDrive() != HAL_OK)
  {
    Error_Handler();
  }

  /** Initializes the CPU, AHB and APB buses clocks
  */
  RCC_ClkInitStruct.ClockType = RCC_CLOCKTYPE_HCLK|RCC_CLOCKTYPE_SYSCLK
                              |RCC_CLOCKTYPE_PCLK1|RCC_CLOCKTYPE_PCLK2;
  RCC_ClkInitStruct.SYSCLKSource = RCC_SYSCLKSOURCE_PLLCLK;
  RCC_ClkInitStruct.AHBCLKDivider = RCC_SYSCLK_DIV1;
  RCC_ClkInitStruct.APB1CLKDivider = RCC_HCLK_DIV4;
  RCC_ClkInitStruct.APB2CLKDivider = RCC_HCLK_DIV2;

  if (HAL_RCC_ClockConfig(&RCC_ClkInitStruct, FLASH_LATENCY_6) != HAL_OK)
  {
    Error_Handler();
  }
}

void PeriphCommonClock_Config(void)
{
  RCC_PeriphCLKInitTypeDef PeriphClkInitStruct = {0};

  /** Initializes the peripherals clock
  */
  PeriphClkInitStruct.PeriphClockSelection = RCC_PERIPHCLK_LTDC|RCC_PERIPHCLK_CLK48;
  PeriphClkInitStruct.PLLSAI.PLLSAIN = 384;
  PeriphClkInitStruct.PLLSAI.PLLSAIR = 5;
  PeriphClkInitStruct.PLLSAI.PLLSAIQ = 2;
  PeriphClkInitStruct.PLLSAI.PLLSAIP = RCC_PLLSAIP_DIV8;
  PeriphClkInitStruct.PLLSAIDivQ = 1;
  PeriphClkInitStruct.PLLSAIDivR = RCC_PLLSAIDIVR_8;
  PeriphClkInitStruct.Clk48ClockSelection = RCC_CLK48SOURCE_PLLSAIP;
  if (HAL_RCCEx_PeriphCLKConfig(&PeriphClkInitStruct) != HAL_OK)
  {
    Error_Handler();
  }
}

/* USER CODE BEGIN 4 */

void HAL_CAN_RxFifo0MsgPendingCallback(CAN_HandleTypeDef *hcan) {
	CAN_RxHeaderTypeDef RxHeader;
	uint8_t RxData[4];

	char test[50]={};

	extern osMessageQId myQueue02Handle;
	//extern osMessageQId MessagerieBatterieHandle;

	Message coup={1,0,0,0};
	//alumé LED

	HAL_CAN_GetRxMessage(&hcan1, CAN_RX_FIFO0, &RxHeader, RxData);
	//if (RxHeader.StdId == 0x410 ) {//égal un autre joueur != notre
		coup.playerID=RxData[0];
		coup.couleur=RxData[1];
		coup.valeur=RxData[2];
		coup.prochain=RxData[3];
		sprintf(test,"x%d",(char) coup.prochain);
		BSP_LCD_DisplayStringAt(-10,70,(uint8_t*) test ,CENTER_MODE);
		xQueueSendFromISR(myQueue02Handle, &coup, NULL);
	//}
	//if (RxHeader.StdId == 0x310) {//à notre id, on ignore
	//	NiveauBatterie = RxData[0];
	//	xQueueSendFromISR(myQueue02Handle, &, NULL);
	//}
}

/* USER CODE END 4 */

void HAL_TIM_PeriodElapsedCallback(TIM_HandleTypeDef *htim)
{
  if (htim->Instance == TIM6) {
    HAL_IncTick();
  }
}

void Error_Handler(void)
{
	__disable_irq();
	while (1)
	{
	}
}

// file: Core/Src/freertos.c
/* USER CODE BEGIN Header */
/**
 ******************************************************************************
 * File Name          : freertos.c
 * Description        : Code for freertos applications
 ******************************************************************************
 * @attention
 *
 * Copyright (c) 2023 STMicroelectronics.
 * All rights reserved.
 *
 * This software is licensed under terms that can be found in the LICENSE file
 * in the root directory of this software component.
 * If no LICENSE file comes with this software, it is provided AS-IS.
 *
 ******************************************************************************
 */
/* USER CODE END Header */

#include "FreeRTOS.h"
#include "task.h"
#include "main.h"
#include "cmsis_os.h"

/* USER CODE BEGIN Includes */

#include "cmsis_os.h"
#include "adc.h"
//#include "dac.h"
#include "dma2d.h"
#include "i2c.h"
#include "ltdc.h"
#include "rtc.h"
//#include "spi.h" pour bus CAN
#include "tim.h"
#include "usart.h"
#include "gpio.h"
#include "fmc.h"

#include "stm32746g_discovery_lcd.h"
#include "stm32746g_discovery_ts.h"
#include "stdio.h"
#include "rtc.h"
//#include "HorombeRGB565.h"
#include "BLEU.h"
#include "ROUGE.h"
#include "JAUNE.h"
#include "Vert.h"

/* USER CODE END Includes */

/* USER CODE BEGIN PTD */
struct game{
	uint8_t nombre[5];//pioche,J1 J2 J3 J4//19*4+8*4-7*4=72
	int8_t cartes[8][2];//carte centre, main1,2,3,..7:[8,2]:2 rouge [0,0] si vide
	uint8_t game_state[3];//flag_actuel,sens_rot,timer_uno
}state={ {72,7,7,7,7},
	{ {8,2}  ,{5,10},{6,11},{7,11},{6,10},{8,12},{8,7},{7,12} },
	{1,1,0}};

/* USER CODE END PTD */

/* USER CODE BEGIN Variables */

//

int ID=1;//La variable à changer pour décider de la position sur la table
static TS_StateTypeDef  TS_State;//pour toucher écran exprès délai

//
/* USER CODE END Variables */
osThreadId defaultTaskHandle;
osThreadId tache1Handle;
osThreadId tache3Handle;
osThreadId tache4Handle;
osMessageQId myQueue02Handle;
osMutexId Mutex_layerHandle;

void StartDefaultTask(void const * argument);
void affichage_1(void const * argument);
void update_state(void const * argument);
void touch_confirm(void const * argument);

void MX_FREERTOS_Init(void); /* (MISRA C 2004 rule 8.1) */

/* GetIdleTaskMemory prototype (linked to static allocation support) */
void vApplicationGetIdleTaskMemory( StaticTask_t **ppxIdleTaskTCBBuffer, StackType_t **ppxIdleTaskStackBuffer, uint32_t *pulIdleTaskStackSize );

/* USER CODE BEGIN GET_IDLE_TASK_MEMORY */
static StaticTask_t xIdleTaskTCBBuffer;
static StackType_t xIdleStack[configMINIMAL_STACK_SIZE];

void vApplicationGetIdleTaskMemory( StaticTask_t **ppxIdleTaskTCBBuffer, StackType_t **ppxIdleTaskStackBuffer, uint32_t *pulIdleTaskStackSize )
{
	*ppxIdleTaskTCBBuffer = &xIdleTaskTCBBuffer;
	*ppxIdleTaskStackBuffer = &xIdleStack[0];
	*pulIdleTaskStackSize = configMINIMAL_STACK_SIZE;
	/* place for user code */
}
/* USER CODE END GET_IDLE_TASK_MEMORY */

void MX_FREERTOS_Init(void) {
  /* Create the mutex(es) */
  /* definition and creation of Mutex_layer */
  osMutexDef(Mutex_layer);
  Mutex_layerHandle = osMutexCreate(osMutex(Mutex_layer));

  /* Create the queue(s) */
  /* definition and creation of myQueue02 */
  osMessageQDef(myQueue02, 32, Message);
  myQueue02Handle = osMessageCreate(osMessageQ(myQueue02), NULL);

  /* Create the thread(s) */
  /* definition and creation of defaultTask */
  osThreadDef(defaultTask, StartDefaultTask, osPriorityNormal, 0, 128);
  defaultTaskHandle = osThreadCreate(osThread(defaultTask), NULL);

  /* definition and creation of tache1 */
  osThreadDef(tache1, affichage_1, osPriorityAboveNormal, 0, 1024);
  tache1Handle = osThreadCreate(osThread(tache1), NULL);

  /* definition and creation of tache3 */
  osThreadDef(tache3, update_state, osPriorityHigh, 0, 1024);
  tache3Handle = osThreadCreate(osThread(tache3), NULL);

  /* definition and creation of tache4 */
  osThreadDef(tache4, touch_confirm, osPriorityAboveNormal, 0, 128);
  tache4Handle = osThreadCreate(osThread(tache4), NULL);

}

void StartDefaultTask(void const * argument)
{
  /* USER CODE BEGIN StartDefaultTask */
	/* Infinite loop */
	for(;;)
	{
		//HAL_GPIO_WritePin(LED13_GPIO_Port,LED13_Pin,1);
		//HAL_GPIO_WritePin(LED13_GPIO_Port,LED13_Pin,0);
		osDelay(100);
	}
  /* USER CODE END StartDefaultTask */
}

void affichage_1(void const * argument)
{
  /* USER CODE BEGIN affichage_1 */

	//Au final non? on va laisser Tout en background,
	//on affiche pas la carte dessous et on laisse tach2 faire

	extern int ID;

	TickType_t LastCall=xTaskGetTickCount();
	TickType_t value=1000;//environ 33 pour 30FPS

	int nb_cartes=7;
	char text[50]={};//agit comme un buffer pour les numeros cartes en main
	char inter[50]={};
	char j_1[50]={};
	char j_2[50]={};
	char j_3[50]={};
	char centre[50]={};
	char pioche[50]={};
	char msg[50]={};
	int X_main=50;
	int Y_main=300;

	//variables globales state : etat de la table

	//choisir le font du BSP LCD taille police et couleur

	/* Infinite loop */

	for(;;)
	{
		//on affiche ici le blink du UNO,le playing flag, et la carte du dessous

		xSemaphoreTake(Mutex_layerHandle,10);

		BSP_LCD_SelectLayer(1);

		BSP_LCD_Clear(00);

		//les 7 cartes en main utilisen la var global/tableau game_state.hand
		//avec color et number (et le nombre de cartes en main/une carte de stop valeur 0?)

		sprintf(text,"        ");//bon nb d'espaces??
		sprintf(inter," ");
		for(int i=0;i<8;i++){//[0,0] si pas de cartes

			//carte au centre, de X... et de Y...
			if (i==0){
				X_main=200;
				Y_main=100;
			}else{
				X_main=50;
				Y_main=250;
				//sprintf(&text+strlen(text),"%s    %d  ",text,(char)state.cartes[i][1]);//le bon nombre espaces

				if(state.cartes[i][1]<=9 && state.cartes[i][1]>=0){//nombre
				sprintf(inter,"     %d",(char)state.cartes[i][1]);}
				if(state.cartes[i][1]==12){//changement sens
				sprintf(inter,"     %%");}
				if(state.cartes[i][1]==10){//pioche 2 cartes
				sprintf(inter,"     !");}
				if(state.cartes[i][1]==11){
				sprintf(inter,"     #");}

				//UNE VALEUR DE 1 POUR AIT PIOCHE UNE CARTE
				//le mettre sur l'écran
				strcat(text,(char*) inter);
			}

			if (state.cartes[i][0]==8){//red
				BSP_LCD_DrawBitmap(X_main+i*40,Y_main,(uint8_t*) _acROUGE);
			}
			if (state.cartes[i][0]==7){//blue
				BSP_LCD_DrawBitmap(X_main+i*40,Y_main,(uint8_t*) _acBLEU);
			}
			if (state.cartes[i][0]==6){//green
				BSP_LCD_DrawBitmap(X_main+i*40,Y_main,(uint8_t*) _acVERT);
			}
			if (state.cartes[i][0]==5){//Yelllow
				BSP_LCD_DrawBitmap(X_main+i*40,Y_main,(uint8_t*) _acJAUNE);
			}

		}
		BSP_LCD_DisplayStringAtLine(20,(uint8_t*)text);//aligné avec les trous des images

		//Afficher le nombre de cartes en main des autres joueurs
		//pas immédiatemetn important? on relache le mutex?

		xSemaphoreGive(Mutex_layerHandle);
		xSemaphoreTake(Mutex_layerHandle,10);

		//game_state.hand_size chaque joueur donne périodiquement
		//le nombre de cartes en main disponibles

		//il faut TROUVER ALIGNEMENT NB LIGNES
		//sur des lignes différentes pour ne pas overlap?
		//aussi le nombre de cartes dans la pioche

		//i correspond à chaque joueur, de 1 à 4
		//donc grace à NOTRE numéro joueur, on en déduit pos relative
		for(int i=0;i<4;i++){
			if(i-ID==0){}//rien faire, c'est nous, mais on l'enverra
			if((i-ID==1) || (i-ID==-3)){//position relative à gauche/suivant

				sprintf(j_1,"         x%d",(char)state.nombre[i+1]);
				BSP_LCD_DisplayStringAtLine(4,(uint8_t*) j_1);//LEFT MODE sous entendu
			}
			if((i-ID)== 2 || (i-ID)== -2){//position relative en face + ou - 2/ ou c'est nous
				sprintf(j_2,"x%d",(char)state.nombre[i+1]);
				BSP_LCD_DisplayStringAt(0,1,(uint8_t*)j_2,CENTER_MODE);//les Y en pixel desormais
			}
			if((i-ID)==-1 || (i-ID==3)){//position relative à Droite/precedent
				sprintf(j_3,"x%d",(char)state.nombre[i+1]);
				BSP_LCD_DisplayStringAt(50,50,(uint8_t*)j_3,RIGHT_MODE);
			}

			//Affichage de la carte au centre et de la pioche
			sprintf(pioche,"x%d",(char)state.nombre[0]);
			BSP_LCD_DisplayStringAt(25,110,(char*) pioche,RIGHT_MODE);

			sprintf(centre,"x   %d",(char)state.cartes[0][1]);
			BSP_LCD_DisplayStringAt(-10,90,(char*) centre,CENTER_MODE);

			//Affichage du flag jeu en cours en fonction de state.game_state[0] qui joue

			sprintf(msg,"%d",(char)state.game_state[0]);
			BSP_LCD_DisplayStringAt(-10,50,(char*) msg,CENTER_MODE);

			xSemaphoreGive(Mutex_layerHandle);
		}

		BSP_LCD_SetBackColor(00);
		xSemaphoreGive(Mutex_layerHandle);
		vTaskDelayUntil(&LastCall,value);
	}
  /* USER CODE END affichage_1 */
}

void update_state(void const * argument)
{
  /* USER CODE BEGIN update_state */

	TickType_t LastCall=xTaskGetTickCount();
	TickType_t value=300;//environ 33 pour 30FPS

	char msg[50]={};
	char tour[50]={};

	Message recu;//on recoit qui a joué quelle carte
	//PAS une var globale mais juste le meme nom/strucuture

	/* Infinite loop */
	for(;;)
	{
		if(xQueueReceive(myQueue02Handle, &recu, 10)==pdPASS){//10ms au pire, plus rapide que les clics sur écran

		//TEST
		sprintf(msg,"on se crie %d dessus %d",(char)recu.couleur,(char)recu.playerID);
		BSP_LCD_DisplayStringAtLine(15,(char*) msg);

		//on modifie alors le game state

		state.nombre[recu.playerID]--;//commencent à 1 donc bien l'indice

		if(recu.couleur!=0){//couleur 0 est le ppas de cartes : [0,0] pour etre sur
		state.cartes[0][0]=recu.couleur;// efface la carte au centre si il n'y a rien
		state.cartes[0][1]=recu.valeur;
		}

		if(recu.prochain==-1){
			state.game_state[1]=-1;
		}
		else{state.game_state[1]= 1;}
		//MODULO 2 CAR 2 JOUEURS
		state.game_state[0]=(int)(state.game_state[0]+(int)state.game_state[1]*recu.prochain)%2+1;//pour revenir à 1 si "4 " dit +1

		sprintf(tour,"Au tour de :  %d",(char) state.game_state[0]);
		BSP_LCD_DisplayStringAt(-10,200,(uint8_t*) tour,CENTER_MODE);
	}//erreur probable car types
		else{

			sprintf(msg,"YA rien ");
			BSP_LCD_DisplayStringAtLine(15,(uint8_t*) msg);
		}
		vTaskDelayUntil(&LastCall,value);
	}

  /* USER CODE END update_state */
}

void touch_confirm(void const * argument)
{
  /* USER CODE BEGIN touch_confirm */
	//on ne va pas tout le temps vérifier si le joueur appuie
	//ce qui implique une tache à grande période qui verifie
	//SI est est reveillée si on touche l'écran et sa pos
	TickType_t LastCall=xTaskGetTickCount();
	TickType_t value=300;
	extern TS_StateTypeDef TS_State;
	//au 1/3 de seconde près

	Message action;//un coup joué
	extern struct game state;
	extern int ID;
	uint8_t TxData1[4];
	//uint8_t TxData2[8];//pas de TX2
	//uint8_t RxData[8];//reception en tant qu'interruption
	uint32_t TxMailbox;
	uint32_t truc_can;
	extern CAN_HandleTypeDef hcan1;
	extern CAN_TxHeaderTypeDef TxHeader1;

	//copie colle de MCU
	TxHeader1.StdId = 0x410;
	TxHeader1.ExtId = 0x01; //peu importe, on est en ID 11 bits (CAN_ID_STD)
	TxHeader1.RTR = CAN_RTR_DATA;
	TxHeader1.IDE = CAN_ID_STD;
	TxHeader1.DLC = 4;
	TxHeader1.TransmitGlobalTime = DISABLE;

	int pos_carte=0;
	/* Infinite loop */
	for(;;)
	{
		pos_carte=1;

		if (state.game_state[0]==ID){//ID, notre propre numero de joueur

			BSP_TS_GetState(&TS_State);//si c'est à notre tour,
			//on regarde si on appuie sur écran et on envoie la position des cartes
			if(TS_State.touchDetected){
				//BSP_LCD_FillCircle(TS_State.touchX[0],TS_State.touchY[0],4);
				if(TS_State.touchY[0]>230){//le Ymain mais avec une marge
					for(int i=0;i<7;i++){//i=0 est la carte au centre donc décalage
						if(TS_State.touchX[0]>50+(i+1)*40 && TS_State.touchX[0]<50+(i+1+1)*40){
							action.couleur=state.cartes[i+1][0];//on check sur quelle carte on a appuyé et
							action.valeur=state.cartes[i+1][1];//on stocke ses parametres
							pos_carte=i+1;
						}
					}
					//on check si carte valide

					//pas 00
					//fonctionne sur le tas

				//on checck si le action est valide avant de l'envoyer
				if(state.cartes[0][0]==action.couleur || state.cartes[0][1] ==action.valeur ){

				//maintenant on a touché une carte légale
				//on enleve de la main
				state.cartes[pos_carte][0]=0;
				state.cartes[pos_carte][1]=0;

				//on prépare le reste de la chaine à envoyer
				action.playerID=ID;

				if (action.valeur<0){//carte sens inverse
				action.prochain=-1;}
				if (action.valeur==10){
					action.prochain=1;//+1 normal
				}
				if(action.valeur==11){
					action.prochain=2;//+2passe tour
				}

				//+1 si normal;+2 si passe *(-1) si changement de sense

				//valeur intermediaire si coup illegal? action.couleur=
				// ENVOYER SUR LE BUS CAN
				TxData1[0] = action.playerID;
				TxData1[1] = action.couleur;
				TxData1[2] = action.valeur;
				TxData1[3] = action.prochain;
				HAL_CAN_AddTxMessage(&hcan1, &TxHeader1, TxData1, &truc_can);

				//on change state en fonction de action, on reprend le code de update_state
				// -------------------------------------------------------------------------------

				//on a encore dans le if carte legale

				if(action.couleur!=0){//couleur 0 est le pas de cartes/pioche? : [0,0] pour etre sur
						state.cartes[0][0]=action.couleur;// efface la carte au centre si il n'y a rien
						state.cartes[0][1]=action.valeur;
						}
				else{
					//A 2 joueur, le joueur a son nb de carte qui augmente de 1

				}

				//pas besoin de changer son propre nb carte en main
				//state.nombre[action.playerID]--;

				if(action.prochain==-1){
					state.game_state[1]=-1;
				}
				else{state.game_state[1]= 1;}
				//MODULO 2 CAR 2 JOUEURS
				state.game_state[0]=(int)(state.game_state[0]+(int)state.game_state[1]*action.prochain)%2+1;//pour revenir à 1 si "4 " dit +1
				// -------------------------------------------------------------------------------

				//on a modifier les autres,
				//on change NOTRE state apres le }else ei

				}
				else if(TS_State.touchY[0]>100 && TS_State.touchY[0]<200){
					//piochage de cartes
					if(TS_State.touchX[0]>300 && TS_State.touchX[0]<450){
						//on a correctement appuyé et on envoie

						//on cherche la carte en main vide
						for(int i=0;i<7;i++){//7 cartes maxi, sinon on envoie pioche de 0 cartes
							if (state.cartes[i+1][0]==0 && state.cartes[i+1][1]==0){//vide
								pos_carte=i+1;
								break;
							}
							}

						//on génère une carte àleéatoiremetn à la position pos_carte

						//UNE VALEUR DE 1 POUR AIT PIOCHE UNE CARTE

						//on envoie sur le CAN on a pioché 1 carte
						action.playerID=ID;
						action.couleur=0;//pioche
						action.valeur=1;//on a pioché 1 carte puis fin de notre tour
						action.prochain=1;//sens normal

						TxData1[0] = action.playerID;
						TxData1[1] = action.couleur;
						TxData1[2] = action.valeur;
						TxData1[3] = action.prochain;
						HAL_CAN_AddTxMessage(&hcan1, &TxHeader1, TxData1, &truc_can);

					}
				}

			}
		}
		}

		vTaskDelayUntil(&LastCall,value);
	}
  /* USER CODE END touch_confirm */
}
